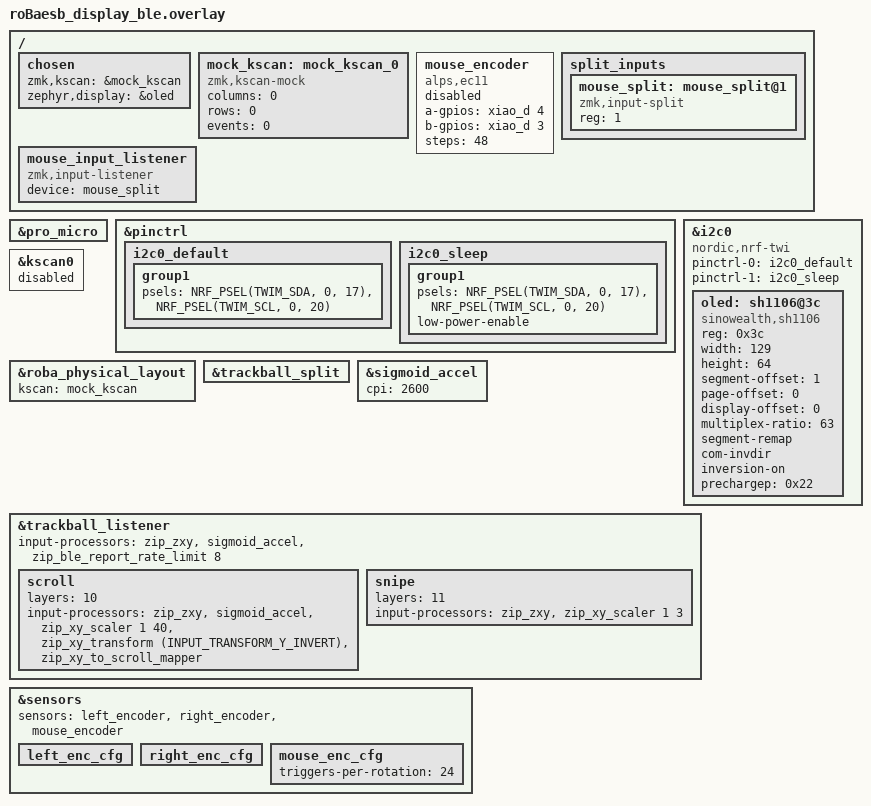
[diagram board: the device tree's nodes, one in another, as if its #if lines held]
xiao_d: &pro_micro {};

#include "../roBa/roBa.dtsi"
#ifdef ZMK_ESB_ADDR_B
#include "roBaesb_addr_b.dtsi"
#else
#include "roBaesb_addr.dtsi"
#endif
#ifdef ZMK_ESB_MOUSE
#include "roBaesb_lariska_transform.dtsi"
#endif

#include <input/processors/xyz.dtsi>
#include <input/processors/report_rate_limit.dtsi>
#include <behaviors/input_processor_sigmoid_accel.dtsi>

/ {
    chosen {
        zmk,kscan = &mock_kscan;
        zephyr,display = &oled;
    };

    mock_kscan: mock_kscan_0 {
        compatible = "zmk,kscan-mock";
        columns = <0>;
        rows = <0>;
        events = <0>;
    };

#ifdef ZMK_ESB_MOUSE
    mouse_encoder: mouse_encoder {
        compatible = "alps,ec11";
        a-gpios = <&xiao_d 4 (GPIO_ACTIVE_HIGH | GPIO_PULL_UP)>;
        b-gpios = <&xiao_d 3 (GPIO_ACTIVE_HIGH | GPIO_PULL_UP)>;
        steps = <48>;
        status = "disabled";
    };

    split_inputs {
        mouse_split: mouse_split@1 {
            compatible = "zmk,input-split";
            reg = <1>;
            status = "okay";
        };
    };

    mouse_input_listener: mouse_input_listener {
        compatible = "zmk,input-listener";
        status = "okay";
        device = <&mouse_split>;
    };
#endif
};

&pinctrl {
    i2c0_default: i2c0_default {
        group1 {
            psels = <NRF_PSEL(TWIM_SDA, 0, 17)>,
                <NRF_PSEL(TWIM_SCL, 0, 20)>;
        };
    };

    i2c0_sleep: i2c0_sleep {
        group1 {
            psels = <NRF_PSEL(TWIM_SDA, 0, 17)>,
                <NRF_PSEL(TWIM_SCL, 0, 20)>;
            low-power-enable;
        };
    };
};

&i2c0 {
    status = "okay";
    compatible = "nordic,nrf-twi";
    pinctrl-0 = <&i2c0_default>;
    pinctrl-1 = <&i2c0_sleep>;

    oled: sh1106@3c {
        compatible = "sinowealth,sh1106";
        reg = <0x3c>;
        width = <129>;
        height = <64>;
        segment-offset = <1>;
        page-offset = <0>;
        display-offset = <0>;
        multiplex-ratio = <63>;
        segment-remap;
        com-invdir;
        inversion-on;
        prechargep = <0x22>;
    };
};

&kscan0 {
    status = "disabled";
};

&roba_physical_layout {
    kscan = <&mock_kscan>;
};

&trackball_split {
    status = "okay";
};

&sigmoid_accel {
    cpi = <2600>;
};

&trackball_listener {
    status = "okay";
    input-processors = <&zip_zxy>, <&sigmoid_accel>, <&zip_ble_report_rate_limit 8>;

    scroll {
        layers = <10>;
        input-processors = <&zip_zxy>, <&sigmoid_accel>, <&zip_xy_scaler 1 40>, <&zip_xy_transform (INPUT_TRANSFORM_Y_INVERT)>, <&zip_xy_to_scroll_mapper>;
    };

    snipe {
        layers = <11>;
        input-processors = <&zip_zxy>, <&zip_xy_scaler 1 3>;
    };
};

#ifdef ZMK_ESB_MOUSE
&sensors {
    sensors = <&left_encoder &right_encoder &mouse_encoder>;
    left_enc_cfg: left_enc_cfg {};
    right_enc_cfg: right_enc_cfg {};
    mouse_enc_cfg: mouse_enc_cfg {
        triggers-per-rotation = <24>;
    };
};
#endif
